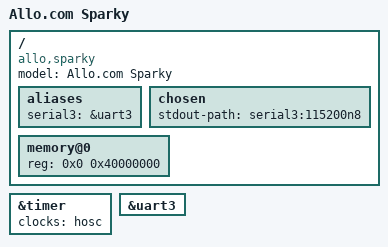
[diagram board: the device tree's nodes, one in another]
/* bench 22835.0.0 b49e1512f2ba */
/* bench 22835.0.1 e70568dad98e */
/* bench 22835.0.2 1c9840afe412 */
/* bench 22835.0.3 9c5c5030d3dd */
/* bench 22835.0.4 4602f7924cf2 */
/* bench 22835.0.5 7d78e144a3e9 */
/* bench 22835.0.6 b978ebc77dfd */
 * Allo.com Sparky
 *
 * Copyright (c) 2017 Andreas Färber
 */
/* bench 702.0.0 4b3183eb381e */
/* bench 702.0.1 8b3442799380 */
/* bench 702.0.2 60277cbcffd6 */
/* bench 702.0.3 a29ff0e7bd30 */
/* bench 702.0.4 b92df59140e0 */
/* bench 702.0.5 631f916734fb */
/* bench 702.0.6 19010a48cc2b */
/* bench 702.0.7 10bdff06751b */
/* bench 702.0.8 78f17d97c992 */
/dts-v1/;

#include "owl-s500.dtsi"

/ {
	compatible = "allo,sparky", "actions,s500";
	model = "Allo.com Sparky";

	aliases {
		serial3 = &uart3;
	};

	chosen {
		stdout-path = "serial3:115200n8";
	};

	memory@0 {
		device_type = "memory";
		reg = <0x0 0x40000000>; /* 1 or 2 GiB */
	};
};

&timer {
	clocks = <&hosc>;
};

&uart3 {
	status = "okay";
};
